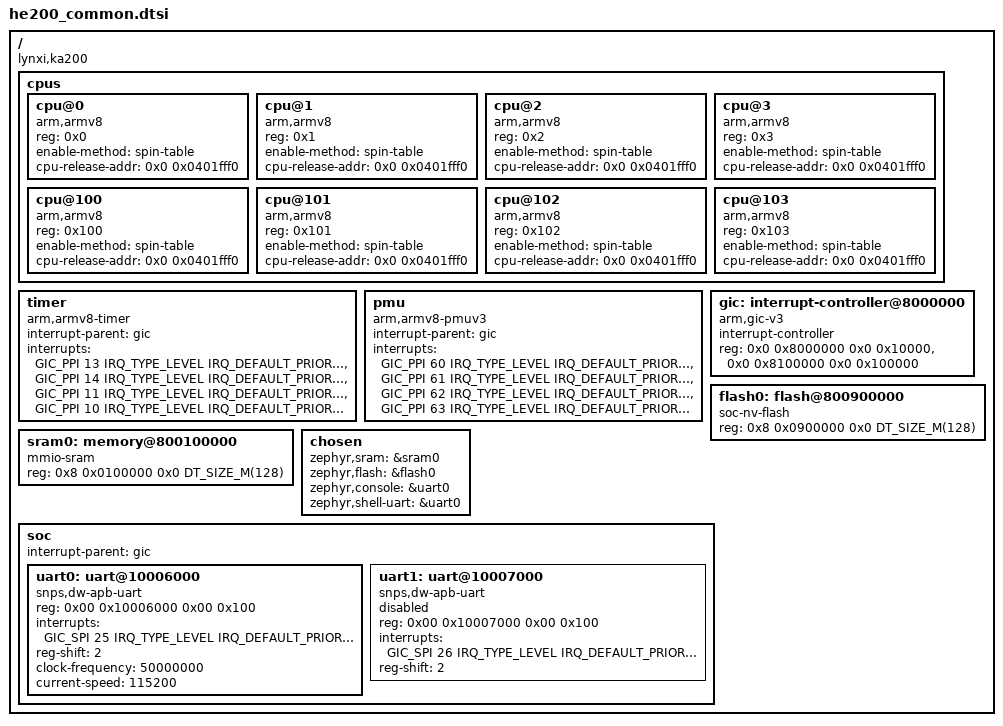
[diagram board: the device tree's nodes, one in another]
/*
 * Copyright (c) 2024 Lynxi Technologies Co., Ltd.
 * SPDX-License-Identifier: Apache-2.0
 */

#include <mem.h>
#include <arm64/armv8-a.dtsi>
#include <zephyr/dt-bindings/gpio/gpio.h>
#include <zephyr/dt-bindings/interrupt-controller/arm-gic.h>
#include "he200_peripherals.dtsi"

/ {
	compatible = "lynxi,ka200";
	#address-cells = <2>;
	#size-cells = <2>;

	cpus {
		#address-cells = <1>;
		#size-cells = <0>;

		cpu@0 {
			device_type = "cpu";
			compatible = "arm,armv8";
			reg = <0x0>;
			enable-method = "spin-table";
			cpu-release-addr = <0x0 0x0401fff0>;
		};
		cpu@1 {
			device_type = "cpu";
			compatible = "arm,armv8";
			reg = <0x1>;
			enable-method = "spin-table";
			cpu-release-addr = <0x0 0x0401fff0>;
		};
		cpu@2 {
			device_type = "cpu";
			compatible = "arm,armv8";
			reg = <0x2>;
			enable-method = "spin-table";
			cpu-release-addr = <0x0 0x0401fff0>;
		};
		cpu@3 {
			device_type = "cpu";
			compatible = "arm,armv8";
			reg = <0x3>;
			enable-method = "spin-table";
			cpu-release-addr = <0x0 0x0401fff0>;
		};
		cpu@100 {
			device_type = "cpu";
			compatible = "arm,armv8";
			reg = <0x100>;
			enable-method = "spin-table";
			cpu-release-addr = <0x0 0x0401fff0>;
		};
		cpu@101 {
			device_type = "cpu";
			compatible = "arm,armv8";
			reg = <0x101>;
			enable-method = "spin-table";
			cpu-release-addr = <0x0 0x0401fff0>;
		};
		cpu@102 {
			device_type = "cpu";
			compatible = "arm,armv8";
			reg = <0x102>;
			enable-method = "spin-table";
			cpu-release-addr = <0x0 0x0401fff0>;
		};
		cpu@103 {
			device_type = "cpu";
			compatible = "arm,armv8";
			reg = <0x103>;
			enable-method = "spin-table";
			cpu-release-addr = <0x0 0x0401fff0>;
		};
	};

	timer {
		compatible = "arm,armv8-timer";
		interrupt-parent = <&gic>;
		interrupts = <GIC_PPI 13 IRQ_TYPE_LEVEL IRQ_DEFAULT_PRIORITY>,
			     <GIC_PPI 14 IRQ_TYPE_LEVEL IRQ_DEFAULT_PRIORITY>,
			     <GIC_PPI 11 IRQ_TYPE_LEVEL IRQ_DEFAULT_PRIORITY>,
			     <GIC_PPI 10 IRQ_TYPE_LEVEL IRQ_DEFAULT_PRIORITY>;
	};

	pmu {
		compatible = "arm,armv8-pmuv3";
		interrupt-parent = <&gic>;
		interrupts = <GIC_PPI 60 IRQ_TYPE_LEVEL IRQ_DEFAULT_PRIORITY>,
			     <GIC_PPI 61 IRQ_TYPE_LEVEL IRQ_DEFAULT_PRIORITY>,
			     <GIC_PPI 62 IRQ_TYPE_LEVEL IRQ_DEFAULT_PRIORITY>,
			     <GIC_PPI 63 IRQ_TYPE_LEVEL IRQ_DEFAULT_PRIORITY>;
	};

	gic: interrupt-controller@8000000 {
		compatible = "arm,gic-v3", "arm,gic";
		#interrupt-cells = <4>;
		#address-cells = <2>;
		#size-cells = <2>;
		ranges;
		interrupt-controller;
		reg = <0x0 0x8000000 0x0 0x10000>, <0x0 0x8100000 0x0 0x100000>;
	};

	flash0: flash@800900000 {
		compatible = "soc-nv-flash";
		reg = <0x8 0x0900000 0x0 DT_SIZE_M(128)>;
	};

	sram0: memory@800100000 {
		compatible = "mmio-sram";
		reg = <0x8 0x0100000 0x0 DT_SIZE_M(128)>;
	};

	chosen {
		zephyr,sram = &sram0;
		zephyr,flash = &flash0;
		zephyr,console = &uart0;
		zephyr,shell-uart = &uart0;
	};

	soc {
		#address-cells = <2>;
		#size-cells = <2>;
		ranges;
		interrupt-parent = <&gic>;

		uart0: uart@10006000 {
			compatible = "snps,dw-apb-uart", "ns16550";
			reg = <0x00 0x10006000 0x00 0x100>;
			interrupts = <GIC_SPI 25 IRQ_TYPE_LEVEL IRQ_DEFAULT_PRIORITY>;
			reg-shift = <2>;
			/* RT-Thread UART_REFERENCE_CLOCK / Linux CPR uart0_sclk */
			clock-frequency = <50000000>;
			current-speed = <115200>;
			status = "okay";
		};

		uart1: uart@10007000 {
			compatible = "snps,dw-apb-uart", "ns16550";
			reg = <0x00 0x10007000 0x00 0x100>;
			interrupts = <GIC_SPI 26 IRQ_TYPE_LEVEL IRQ_DEFAULT_PRIORITY>;
			// reg-io-width = <4>;
			reg-shift = <2>;
			status = "disabled";
		};
	};
};
